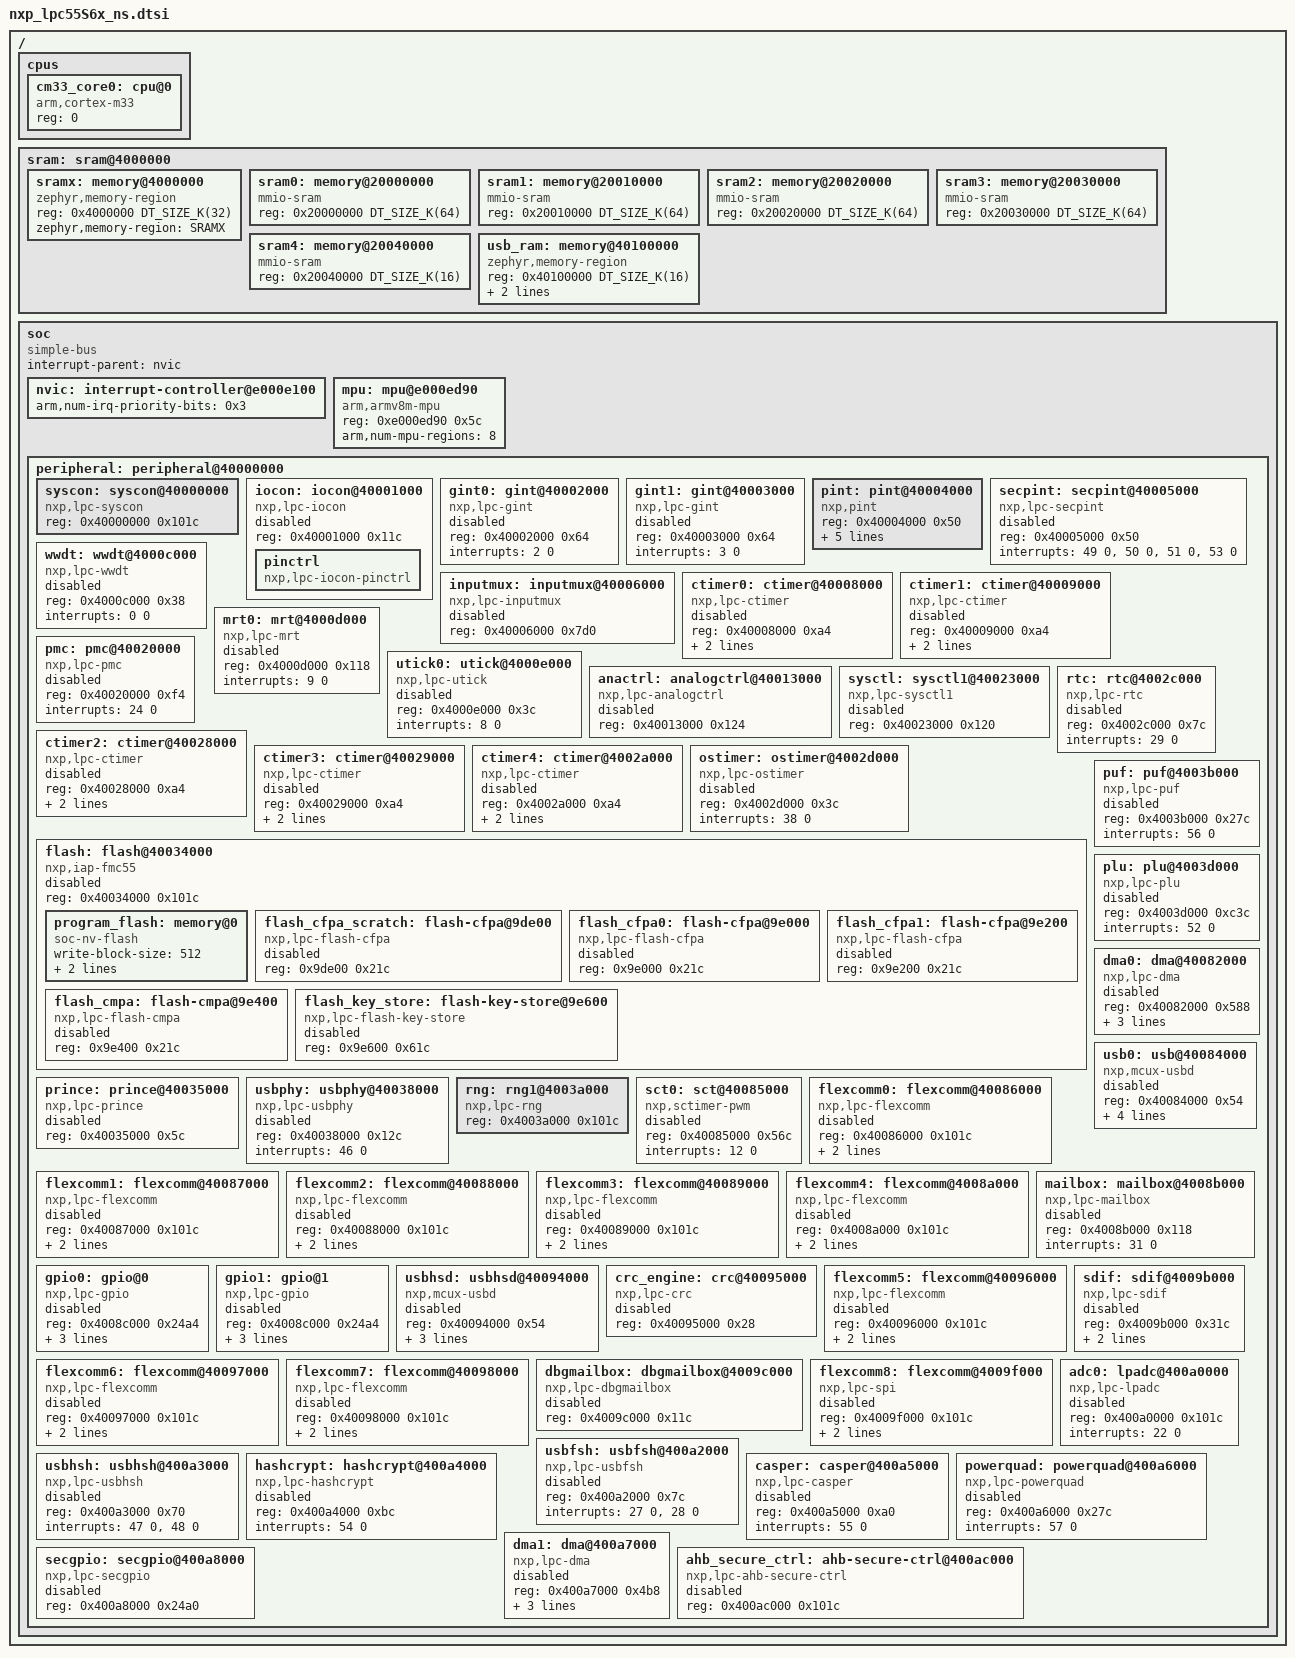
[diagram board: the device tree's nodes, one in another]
/*
 * Copyright (c) 2019,2023 NXP
 *
 * SPDX-License-Identifier: Apache-2.0
 */

/*
 * This file is automatically generated based on the core
 * definition for LPC55S69.
 */

/dts-v1/;

#include <arm/armv8-m.dtsi>
#include <mem.h>
#include <zephyr/dt-bindings/adc/adc.h>
#include <zephyr/dt-bindings/clock/mcux_lpc_syscon_clock.h>
#include <zephyr/dt-bindings/gpio/gpio.h>
#include <zephyr/dt-bindings/i2c/i2c.h>

/ {
	cpus {
		#address-cells = <0x1>;
		#size-cells = <0>;
		cm33_core0: cpu@0 {
			reg = <0>;
			device_type = "cpu";
			compatible = "arm,cortex-m33";
		};

	};

	sram: sram@4000000 {
		ranges = <0x4000000 0x4000000 DT_SIZE_K(984080)>;

		#address-cells = <0x1>;
		#size-cells = <0x1>;
		sramx: memory@4000000 {
			compatible = "zephyr,memory-region", "mmio-sram";
			reg = <0x4000000 DT_SIZE_K(32)>;
			zephyr,memory-region = "SRAMX";
		};

		sram0: memory@20000000 {
			compatible = "mmio-sram";
			reg = <0x20000000 DT_SIZE_K(64)>;
		};

		sram1: memory@20010000 {
			compatible = "mmio-sram";
			reg = <0x20010000 DT_SIZE_K(64)>;
		};

		sram2: memory@20020000 {
			compatible = "mmio-sram";
			reg = <0x20020000 DT_SIZE_K(64)>;
		};

		sram3: memory@20030000 {
			compatible = "mmio-sram";
			reg = <0x20030000 DT_SIZE_K(64)>;
		};

		sram4: memory@20040000 {
			compatible = "mmio-sram";
			reg = <0x20040000 DT_SIZE_K(16)>;
		};

		usb_ram: memory@40100000 {
			compatible = "zephyr,memory-region", "mmio-sram";
			reg = <0x40100000 DT_SIZE_K(16)>;
			zephyr,memory-region = "USB_SRAM";
			zephyr,memory-region-mpu = "RAM";
		};

	};

	soc {
		compatible = "simple-bus";
		interrupt-parent = <&nvic>;

		nvic: interrupt-controller@e000e100 {
			arm,num-irq-priority-bits = <0x3>;
		};

		mpu: mpu@e000ed90 {
			compatible = "arm,armv8m-mpu";
			reg = <0xe000ed90 0x5c>;
			arm,num-mpu-regions = <8>;
		};

		peripheral: peripheral@40000000 {
			#address-cells = <0x1>;
			#size-cells = <0x1>;

			ranges = <0x40000000 0x40000000 DT_SIZE_K(262144)>;

			syscon: syscon@40000000 {
				compatible = "nxp,lpc-syscon";
				status = "okay";
				reg = <0x40000000 0x101c>;
				#clock-cells = <1>;
			};

			iocon: iocon@40001000 {
				compatible = "nxp,lpc-iocon";
				status = "disabled";
				reg = <0x40001000 0x11c>;
				pinctrl: pinctrl {
					compatible = "nxp,lpc-iocon-pinctrl";
				};

			};

			gint0: gint@40002000 {
				compatible = "nxp,lpc-gint";
				status = "disabled";
				reg = <0x40002000 0x64>;
				interrupts = <2 0>;
			};

			gint1: gint@40003000 {
				compatible = "nxp,lpc-gint";
				status = "disabled";
				reg = <0x40003000 0x64>;
				interrupts = <3 0>;
			};

			pint: pint@40004000 {
				compatible = "nxp,pint";
				status = "okay";
				reg = <0x40004000 0x50>;
				interrupts = <4 0>, <5 0>, <6 0>, <7 0>,
					<32 0>, <33 0>, <34 0>, <35 0>;
				interrupt-names = "pin-int0", "pin-int1",
					"pin-int2", "pin-int3", "pin-int4",
					"pin-int5", "pin-int6", "pin-int7";
				num-lines = <8>;
				num-inputs = <64>;
				#interrupt-cells = <1>;
				interrupt-controller;
			};

			secpint: secpint@40005000 {
				compatible = "nxp,lpc-secpint";
				status = "disabled";
				reg = <0x40005000 0x50>;
				interrupts = <49 0>, <50 0>, <51 0>, <53 0>;
				interrupt-names = "sec-hypervisor-call",
					"sec-gpio-int0-irq0",
					"sec-gpio-int0-irq1",
					"sec-vio";
			};

			inputmux: inputmux@40006000 {
				compatible = "nxp,lpc-inputmux";
				status = "disabled";
				reg = <0x40006000 0x7d0>;
			};

			ctimer0: ctimer@40008000 {
				compatible = "nxp,lpc-ctimer";
				status = "disabled";
				reg = <0x40008000 0xa4>;
				clocks = <&syscon MCUX_CTIMER0_CLK>;
				interrupts = <10 0>;
			};

			ctimer1: ctimer@40009000 {
				compatible = "nxp,lpc-ctimer";
				status = "disabled";
				reg = <0x40009000 0xa4>;
				clocks = <&syscon MCUX_CTIMER1_CLK>;
				interrupts = <11 0>;
			};

			wwdt: wwdt@4000c000 {
				compatible = "nxp,lpc-wwdt";
				status = "disabled";
				reg = <0x4000c000 0x38>;
				interrupts = <0 0>;
			};

			mrt0: mrt@4000d000 {
				compatible = "nxp,lpc-mrt";
				status = "disabled";
				reg = <0x4000d000 0x118>;
				interrupts = <9 0>;
			};

			utick0: utick@4000e000 {
				compatible = "nxp,lpc-utick";
				status = "disabled";
				reg = <0x4000e000 0x3c>;
				interrupts = <8 0>;
			};

			anactrl: analogctrl@40013000 {
				compatible = "nxp,lpc-analogctrl";
				status = "disabled";
				reg = <0x40013000 0x124>;
			};

			pmc: pmc@40020000 {
				compatible = "nxp,lpc-pmc";
				status = "disabled";
				reg = <0x40020000 0xf4>;
				interrupts = <24 0>;
			};

			sysctl: sysctl1@40023000 {
				compatible = "nxp,lpc-sysctl1";
				status = "disabled";
				reg = <0x40023000 0x120>;
			};

			ctimer2: ctimer@40028000 {
				compatible = "nxp,lpc-ctimer";
				status = "disabled";
				reg = <0x40028000 0xa4>;
				clocks = <&syscon MCUX_CTIMER2_CLK>;
				interrupts = <36 0>;
			};

			ctimer3: ctimer@40029000 {
				compatible = "nxp,lpc-ctimer";
				status = "disabled";
				reg = <0x40029000 0xa4>;
				clocks = <&syscon MCUX_CTIMER3_CLK>;
				interrupts = <13 0>;
			};

			ctimer4: ctimer@4002a000 {
				compatible = "nxp,lpc-ctimer";
				status = "disabled";
				reg = <0x4002a000 0xa4>;
				clocks = <&syscon MCUX_CTIMER0_CLK>;
				interrupts = <37 0>;
			};

			rtc: rtc@4002c000 {
				compatible = "nxp,lpc-rtc";
				status = "disabled";
				reg = <0x4002c000 0x7c>;
				interrupts = <29 0>;
			};

			ostimer: ostimer@4002d000 {
				compatible = "nxp,lpc-ostimer";
				status = "disabled";
				reg = <0x4002d000 0x3c>;
				interrupts = <38 0>;
			};

			flash: flash@40034000 {
				compatible = "nxp,iap-fmc55";
				status = "disabled";
				reg = <0x40034000 0x101c>;
				#address-cells = <1>;
				#size-cells = <1>;
				status = "disabled";

				program_flash: memory@0 {
					write-block-size = <512>;
					erase-block-size = <512>;
					compatible = "soc-nv-flash";
					reg = <0x0 DT_SIZE_K(630)>;
				};

				flash_cfpa_scratch: flash-cfpa@9de00 {
					compatible = "nxp,lpc-flash-cfpa";
					status = "disabled";
					reg = <0x9de00 0x21c>;
				};

				flash_cfpa0: flash-cfpa@9e000 {
					compatible = "nxp,lpc-flash-cfpa";
					status = "disabled";
					reg = <0x9e000 0x21c>;
				};

				flash_cfpa1: flash-cfpa@9e200 {
					compatible = "nxp,lpc-flash-cfpa";
					status = "disabled";
					reg = <0x9e200 0x21c>;
				};

				flash_cmpa: flash-cmpa@9e400 {
					compatible = "nxp,lpc-flash-cmpa";
					status = "disabled";
					reg = <0x9e400 0x21c>;
				};

				flash_key_store: flash-key-store@9e600 {
					compatible = "nxp,lpc-flash-key-store";
					status = "disabled";
					reg = <0x9e600 0x61c>;
				};

			};

			prince: prince@40035000 {
				compatible = "nxp,lpc-prince";
				status = "disabled";
				reg = <0x40035000 0x5c>;
			};

			usbphy: usbphy@40038000 {
				compatible = "nxp,lpc-usbphy";
				status = "disabled";
				reg = <0x40038000 0x12c>;
				interrupts = <46 0>;
			};

			rng: rng1@4003a000 {
				compatible = "nxp,lpc-rng";
				status = "disabled";
				reg = <0x4003a000 0x101c>;
				status = "okay";
			};

			puf: puf@4003b000 {
				compatible = "nxp,lpc-puf";
				status = "disabled";
				reg = <0x4003b000 0x27c>;
				interrupts = <56 0>;
			};

			plu: plu@4003d000 {
				compatible = "nxp,lpc-plu";
				status = "disabled";
				reg = <0x4003d000 0xc3c>;
				interrupts = <52 0>;
			};

			dma0: dma@40082000 {
				compatible = "nxp,lpc-dma";
				status = "disabled";
				reg = <0x40082000 0x588>;
				interrupts = <1 0>;
				#dma-cells = <1>;
				dma-channels = <23>;
				nxp,dma-num-of-otrigs = <4>;
			};

			usb0: usb@40084000 {
				compatible = "nxp,mcux-usbd";
				status = "disabled";
				reg = <0x40084000 0x54>;
				interrupts = <27 0>, <28 0>;
				interrupt-names = "usb0-needclk", "int-usb0";
				num-bidir-endpoints = <5>;
				usb-controller-index = "LpcIp3511Fs0";
				maximum-speed = "full-speed";
			};

			sct0: sct@40085000 {
				compatible = "nxp,sctimer-pwm";
				status = "disabled";
				reg = <0x40085000 0x56c>;
				interrupts = <12 0>;
				#pwm-cells = <3>;
			};

			flexcomm0: flexcomm@40086000 {
				compatible = "nxp,lpc-flexcomm";
				status = "disabled";
				reg = <0x40086000 0x101c>;
				clocks = <&syscon MCUX_FLEXCOMM0_CLK>;
				interrupts = <14 0>;
			};

			flexcomm1: flexcomm@40087000 {
				compatible = "nxp,lpc-flexcomm";
				status = "disabled";
				reg = <0x40087000 0x101c>;
				clocks = <&syscon MCUX_FLEXCOMM1_CLK>;
				interrupts = <15 0>;
			};

			flexcomm2: flexcomm@40088000 {
				compatible = "nxp,lpc-flexcomm";
				status = "disabled";
				reg = <0x40088000 0x101c>;
				clocks = <&syscon MCUX_FLEXCOMM2_CLK>;
				interrupts = <16 0>;
			};

			flexcomm3: flexcomm@40089000 {
				compatible = "nxp,lpc-flexcomm";
				status = "disabled";
				reg = <0x40089000 0x101c>;
				clocks = <&syscon MCUX_FLEXCOMM3_CLK>;
				interrupts = <17 0>;
			};

			flexcomm4: flexcomm@4008a000 {
				compatible = "nxp,lpc-flexcomm";
				status = "disabled";
				reg = <0x4008a000 0x101c>;
				clocks = <&syscon MCUX_FLEXCOMM4_CLK>;
				interrupts = <18 0>;
			};

			mailbox: mailbox@4008b000 {
				compatible = "nxp,lpc-mailbox";
				status = "disabled";
				reg = <0x4008b000 0x118>;
				interrupts = <31 0>;
				status = "disabled";
			};

			gpio0: gpio@0 {
				compatible = "nxp,lpc-gpio";
				status = "disabled";
				reg = <0x4008c000 0x24a4>;
				gpio-controller;
				int-source = "pint";
				#gpio-cells = <2>;
				port = <0>;
			};

			gpio1: gpio@1 {
				compatible = "nxp,lpc-gpio";
				status = "disabled";
				reg = <0x4008c000 0x24a4>;
				gpio-controller;
				int-source = "pint";
				#gpio-cells = <2>;
				port = <1>;
			};

			usbhsd: usbhsd@40094000 {
				compatible = "nxp,mcux-usbd";
				status = "disabled";
				reg = <0x40094000 0x54>;
				interrupts = <47 0>, <48 0>;
				interrupt-names = "usb1", "usb1-needclk";
				num-bidir-endpoints = <6>;
				usb-controller-index = "LpcIp3511Hs0";
			};

			crc_engine: crc@40095000 {
				compatible = "nxp,lpc-crc";
				status = "disabled";
				reg = <0x40095000 0x28>;
			};

			flexcomm5: flexcomm@40096000 {
				compatible = "nxp,lpc-flexcomm";
				status = "disabled";
				reg = <0x40096000 0x101c>;
				clocks = <&syscon MCUX_FLEXCOMM5_CLK>;
				interrupts = <19 0>;
			};

			flexcomm6: flexcomm@40097000 {
				compatible = "nxp,lpc-flexcomm";
				status = "disabled";
				reg = <0x40097000 0x101c>;
				clocks = <&syscon MCUX_FLEXCOMM6_CLK>;
				interrupts = <20 0>;
			};

			flexcomm7: flexcomm@40098000 {
				compatible = "nxp,lpc-flexcomm";
				status = "disabled";
				reg = <0x40098000 0x101c>;
				clocks = <&syscon MCUX_FLEXCOMM7_CLK>;
				interrupts = <21 0>;
			};

			sdif: sdif@4009b000 {
				compatible = "nxp,lpc-sdif";
				status = "disabled";
				reg = <0x4009b000 0x31c>;
				clocks = <&syscon MCUX_SDIF_CLK>;
				interrupts = <42 0>;
			};

			dbgmailbox: dbgmailbox@4009c000 {
				compatible = "nxp,lpc-dbgmailbox";
				status = "disabled";
				reg = <0x4009c000 0x11c>;
			};

			flexcomm8: flexcomm@4009f000 {
				compatible = "nxp,lpc-spi";
				status = "disabled";
				reg = <0x4009f000 0x101c>;
				interrupts = <59 0>;
				#address-cells = <1>;
				clocks = <&syscon MCUX_HS_SPI_CLK>;
				#size-cells = <0>;
			};

			adc0: lpadc@400a0000 {
				compatible = "nxp,lpc-lpadc";
				status = "disabled";
				reg = <0x400a0000 0x101c>;
				interrupts = <22 0>;
				#io-channel-cells = <1>;
			};

			usbfsh: usbfsh@400a2000 {
				compatible = "nxp,lpc-usbfsh";
				status = "disabled";
				reg = <0x400a2000 0x7c>;
				interrupts = <27 0>, <28 0>;
				interrupt-names = "usb0-needclk", "usb0";
			};

			usbhsh: usbhsh@400a3000 {
				compatible = "nxp,lpc-usbhsh";
				status = "disabled";
				reg = <0x400a3000 0x70>;
				interrupts = <47 0>, <48 0>;
				interrupt-names = "usb1", "usb1-needclk";
			};

			hashcrypt: hashcrypt@400a4000 {
				compatible = "nxp,lpc-hashcrypt";
				status = "disabled";
				reg = <0x400a4000 0xbc>;
				interrupts = <54 0>;
			};

			casper: casper@400a5000 {
				compatible = "nxp,lpc-casper";
				status = "disabled";
				reg = <0x400a5000 0xa0>;
				interrupts = <55 0>;
			};

			powerquad: powerquad@400a6000 {
				compatible = "nxp,lpc-powerquad";
				status = "disabled";
				reg = <0x400a6000 0x27c>;
				interrupts = <57 0>;
			};

			dma1: dma@400a7000 {
				compatible = "nxp,lpc-dma";
				status = "disabled";
				reg = <0x400a7000 0x4b8>;
				interrupts = <58 0>;
				#dma-cells = <1>;
				dma-channels = <10>;
				nxp,dma-num-of-otrigs = <4>;
			};

			secgpio: secgpio@400a8000 {
				compatible = "nxp,lpc-secgpio";
				status = "disabled";
				reg = <0x400a8000 0x24a0>;
			};

			ahb_secure_ctrl: ahb-secure-ctrl@400ac000 {
				compatible = "nxp,lpc-ahb-secure-ctrl";
				status = "disabled";
				reg = <0x400ac000 0x101c>;
			};

		};

	};

};
